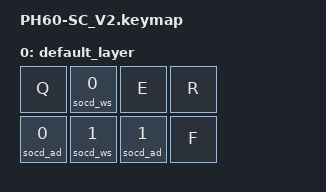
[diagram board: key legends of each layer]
#include <behaviors/socd_wasd.dtsi>

/ {
    keymap {
        compatible = "zmk,keymap";
        default_layer {
            bindings = <
                &kp Q       &socd_ws 0  &kp E       &kp R       ...
                &socd_ad 0  &socd_ws 1  &socd_ad 1  &kp F       ...
            >;
        };
    };
};
